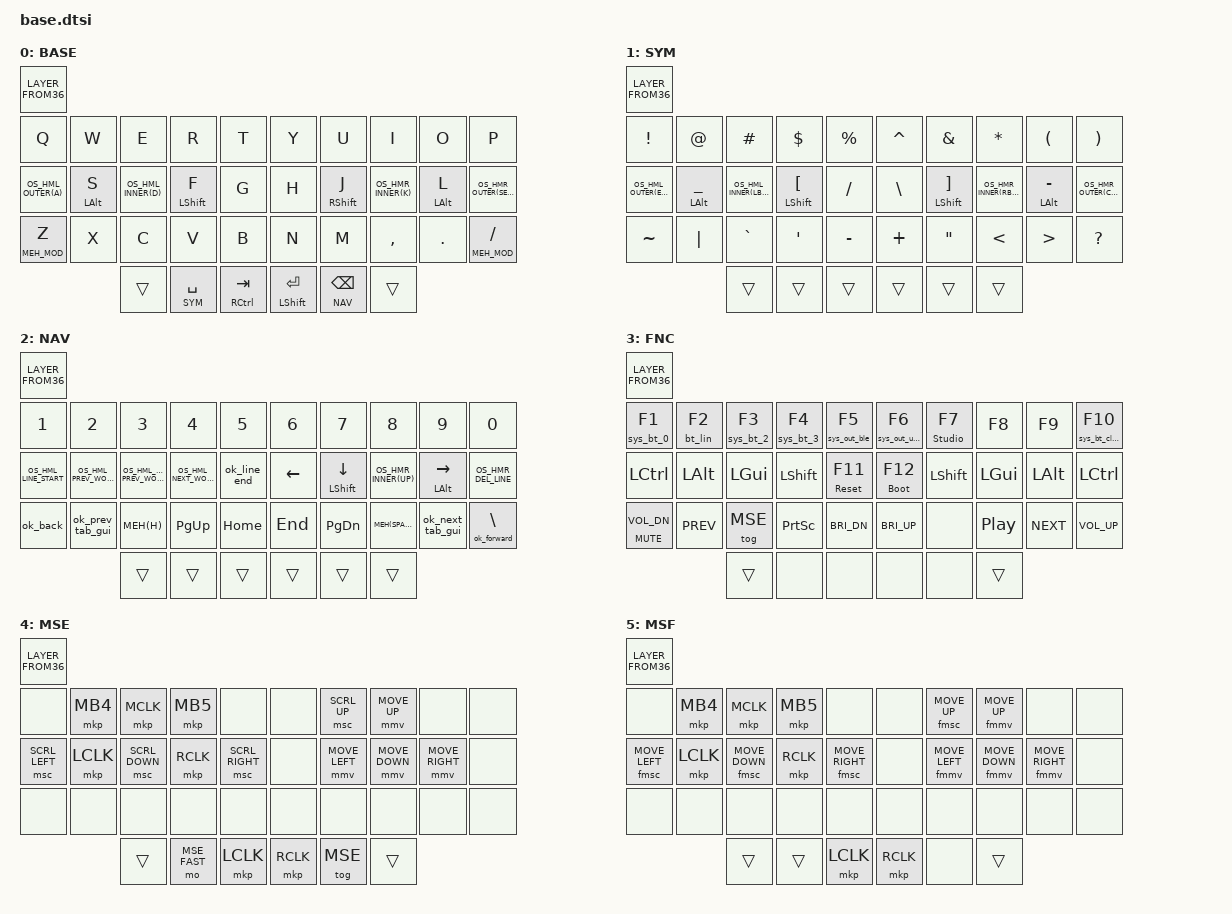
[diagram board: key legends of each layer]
#include <behaviors.dtsi>
#include <dt-bindings/zmk/keys.h>
#include <dt-bindings/zmk/bt.h>
#include <dt-bindings/zmk/oskey.h>
#include <dt-bindings/zmk/outputs.h>
#include <behaviors/rgbled_widget.dtsi> // rgb led indicator for battery and connection
#include <behaviors/case_mode.dtsi> // case_modes behaviors

// Layer definitions
#define BASE 0
#define SYM 1
#define NAV 2
#define FNC 3
#define MSE 4
#define MSE_FAST 5

#define MEH(k) LC(LA(LS(k)))
#define MEH_MOD LA(LS(LCTRL))

#include "mouse.dtsi"
#include "oskey.dtsi"
#include "combos.dtsi"

&caps_word { continue-list = <UNDERSCORE BACKSPACE DELETE MINUS DEL N1 N2 N3 N4 N5 N6 N7 N8 N9 N0>; };

/ {
    macros {
        sys_bt_0: sys_bt_0 {
            compatible = "zmk,behavior-macro";
            #binding-cells = <0>;
            bindings = <&bt BT_SEL 0>;
        };

        bt_lin: bt_lin {
            compatible = "zmk,behavior-macro";
            #binding-cells = <0>;
            bindings = <&bt BT_SEL 1>, <&os_sel OS_LIN>;
        };

        sys_bt_2: sys_bt_2 {
            compatible = "zmk,behavior-macro";
            #binding-cells = <0>;
            bindings = <&bt BT_SEL 2>;
        };

        sys_bt_3: sys_bt_3 {
            compatible = "zmk,behavior-macro";
            #binding-cells = <0>;
            bindings = <&bt BT_SEL 3>;
        };

        sys_out_usb: sys_out_usb {
            compatible = "zmk,behavior-macro";
            #binding-cells = <0>;
            bindings = <&out OUT_USB>;
        };

        sys_out_ble: sys_out_ble {
            compatible = "zmk,behavior-macro";
            #binding-cells = <0>;
            bindings = <&out OUT_BLE>;
        };

        sys_bt_clear: sys_bt_clear {
            compatible = "zmk,behavior-macro";
            #binding-cells = <0>;
            bindings = <&bt BT_CLR>;
        };
    };

   cond_layers {
        compatible = "zmk,conditional-layers";
        // Define FNC layer as tri-state
        func_tristate {
            if-layers = <SYM NAV>;
            then-layer = <FNC>;
        };
    };

    behaviors {
        hmr: hmr {
            compatible = "zmk,behavior-hold-tap";
            bindings = <&kp>, <&kp>;

            #binding-cells = <2>;
            tapping-term-ms = <230>;
            quick-tap-ms = <150>;
            require-prior-idle-ms = <130>;
            flavor = "balanced";
            hold-trigger-key-positions = <KEYS_L THUMBS>;
            hold-trigger-on-release;
        };

        hml: hml {
            compatible = "zmk,behavior-hold-tap";
            bindings = <&kp>, <&kp>;

            #binding-cells = <2>;
            tapping-term-ms = <230>;
            quick-tap-ms = <155>;
            require-prior-idle-ms = <130>;
            flavor = "balanced";
            hold-trigger-key-positions = <KEYS_R THUMBS>;
            hold-trigger-on-release;
        };

        rth: rthumb {
            compatible = "zmk,behavior-hold-tap";
            bindings = <&mo>, <&kp>;
            flavor = "hold-preferred";
            #binding-cells = <2>;
            tapping-term-ms = <200>;
            quick-tap-ms = <130>;
        };

        lth: lthumb {
            compatible = "zmk,behavior-hold-tap";
            bindings = <&mo>, <&kp>;
            flavor = "hold-preferred";
            #binding-cells = <2>;
            tapping-term-ms = <230>;
            quick-tap-ms = <140>;
        };

        hp: hold_priority {
            compatible = "zmk,behavior-hold-tap";
            bindings = <&kp>, <&kp>;
            flavor = "hold-preferred";
            #binding-cells = <2>;
            tapping-term-ms = <230>;
            quick-tap-ms = <150>;
        };

        lsm: left_shift_mode {
            compatible = "zmk,behavior-hold-tap";
            bindings = <&kp>, <&kp>;
            flavor = "hold-preferred";
            #binding-cells = <2>;
            tapping-term-ms = <190>;
            quick-tap-ms = <150>;
            require-prior-idle-ms = <120>;
            hold-trigger-key-positions = <KEYS_R LH0 RH0>;
            //hold-trigger-on-release;
        };

        rsm: right_shift_mode {
            compatible = "zmk,behavior-hold-tap";
            bindings = <&kp>, <&kp>;
            flavor = "hold-preferred";
            #binding-cells = <2>;
            tapping-term-ms = <190>;
            quick-tap-ms = <150>;
            require-prior-idle-ms = <130>;
            hold-trigger-key-positions = <KEYS_L LH0 RH0>;
            //hold-trigger-on-release;
        };

        f1_sys: f1_sys {
            compatible = "zmk,behavior-hold-tap";
            #binding-cells = <2>;
            tapping-term-ms = <3000>;
            flavor = "tap-preferred";
            bindings = <&sys_bt_0>, <&kp>;
        };

        f2_sys: f2_sys {
            compatible = "zmk,behavior-hold-tap";
            #binding-cells = <2>;
            tapping-term-ms = <3000>;
            flavor = "tap-preferred";
            bindings = <&bt_lin>, <&kp>;
        };

        f3_sys: f3_sys {
            compatible = "zmk,behavior-hold-tap";
            #binding-cells = <2>;
            tapping-term-ms = <3000>;
            flavor = "tap-preferred";
            bindings = <&sys_bt_2>, <&kp>;
        };

        f4_sys: f4_sys {
            compatible = "zmk,behavior-hold-tap";
            #binding-cells = <2>;
            tapping-term-ms = <3000>;
            flavor = "tap-preferred";
            bindings = <&sys_bt_3>, <&kp>;
        };

        f5_sys: f5_sys {
            compatible = "zmk,behavior-hold-tap";
            #binding-cells = <2>;
            tapping-term-ms = <3000>;
            flavor = "tap-preferred";
            bindings = <&sys_out_ble>, <&kp>;
        };

        f6_sys: f6_sys {
            compatible = "zmk,behavior-hold-tap";
            #binding-cells = <2>;
            tapping-term-ms = <3000>;
            flavor = "tap-preferred";
            bindings = <&sys_out_usb>, <&kp>;
        };

        f7_sys: f7_sys {
            compatible = "zmk,behavior-hold-tap";
            #binding-cells = <2>;
            tapping-term-ms = <3000>;
            flavor = "tap-preferred";
            bindings = <&studio_unlock>, <&kp>;
        };

        f10_sys: f10_sys {
            compatible = "zmk,behavior-hold-tap";
            #binding-cells = <2>;
            tapping-term-ms = <3000>;
            flavor = "tap-preferred";
            bindings = <&sys_bt_clear>, <&kp>;
        };

        f11_sys: f11_sys {
            compatible = "zmk,behavior-hold-tap";
            #binding-cells = <2>;
            tapping-term-ms = <3000>;
            flavor = "tap-preferred";
            bindings = <&sys_reset>, <&kp>;
        };

        f12_sys: f12_sys {
            compatible = "zmk,behavior-hold-tap";
            #binding-cells = <2>;
            tapping-term-ms = <3000>;
            flavor = "tap-preferred";
            bindings = <&bootloader>, <&kp>;
        };

    };

    keymap {
        compatible = "zmk,keymap";

        base {
            display-name = "BASE";
            bindings = <LAYER_FROM36( \
// ╭─────────────┬─────────────┬─────────────┬─────────────┬─────────────╮   ╭───────────────┬───────────────┬───────────────┬─────────────┬───────────────╮
     &kp Q,        &kp W,        &kp E,        &kp R,        &kp T,            &kp Y,           &kp U,          &kp I,        &kp O,           &kp P,      \
// ├─────────────┼─────────────┼─────────────┼─────────────┼─────────────┤   ├───────────────┼───────────────┼───────────────┼─────────────┼───────────────┤
     OS_HML_OUTER(A), &hml LALT S,  OS_HML_INNER(D), &hml LSHFT F, &kp G,            &kp H,           &hmr RSHFT J, OS_HMR_INNER(K), &hmr LALT L,  OS_HMR_OUTER(SEMI),\
// ├─────────────┼─────────────┼─────────────┼─────────────┼─────────────┤   ├───────────────┼───────────────┼───────────────┼─────────────┼───────────────┤
     &hml MEH_MOD Z,             &kp X,        &kp C,        &kp V,        &kp B,            &kp N,           &kp M,          &kp COMMA,      &kp DOT,     &hmr MEH_MOD SLASH, \
// ╰─────────────┴─────────────┴─────────────┼─────────────┼─────────────┤   ├───────────────┼───────────────┼───────────────┴─────────────┴───────────────╯
                                 &trans,      &lth SYM SPACE, &hp RCTRL TAB,  &hp LSHFT ENTER,  &rth NAV BSPC,   &trans
//                             ╰─────────────┴─────────────┴─────────────╯   ╰───────────────┴───────────────┴─────────────╯
            )>;
        };

        symbol {
          display-name = "SYM";
          bindings = <LAYER_FROM36( \
// ╭───────────────┬───────────────┬───────────────┬────────────────────┬───────────────╮   ╭───────────────┬────────────────────┬────────────────────┬────────────────────┬────────────────────╮
    &kp EXCL,        &kp AT_SIGN,     &kp HASH,        &kp DLLR,           &kp PRCNT,         &kp CARET,       &kp AMPS,            &kp ASTERISK,          &kp LPAR,             &kp RPAR,      \
// ├───────────────┼───────────────┼───────────────┼────────────────────┼───────────────┤   ├───────────────┼────────────────────┼────────────────────┼────────────────────┼────────────────────┤
    OS_HML_OUTER(EQUAL), &hml LALT UNDER, OS_HML_INNER(LBRC), &hml LSHFT LBKT,   &kp SLASH,          &kp BSLH,        &hmr LSHFT RBKT,    OS_HMR_INNER(RBRC),    &hmr LALT MINUS,     OS_HMR_OUTER(COLON), \
// ├───────────────┼───────────────┼───────────────┼────────────────────┼───────────────┤   ├───────────────┼────────────────────┼────────────────────┼────────────────────┼────────────────────┤
      &kp TILDE,       &kp PIPE,       &kp GRAVE,       &kp SQT,            &kp MINUS,         &kp PLUS,        &kp DOUBLE_QUOTES,  &kp LESS_THAN,       &kp GREATER_THAN,     &kp QUESTION,    \
// ╰───────────────┴───────────────┴───────────────┼────────────────────┼───────────────┤   ├───────────────┼────────────────────┴────────────────────┴────────────────────┴────────────────────╯
                                       &trans,          &trans,             &trans,              &trans,        &trans,             &trans       \
//                                 ╰───────────────┴────────────────────┴───────────────╯   ╰───────────────┴────────────────────┴───────────────╯
         )>;
      };

        nav_number {
            display-name = "NAV";
            bindings = <LAYER_FROM36( \
// ╭──────────────────┬───────────────┬────────────────────┬─────────────────┬──────────────╮   ╭────────────────────┬─────────────────┬───────────────┬──────────────────┬─────────────────────╮
     &kp N1,               &kp N2,      &kp N3,              &kp N4,           &kp N5,             &kp N6,             &kp N7,            &kp N8,        &kp N9,            &kp N0,             \
// ├──────────────────┼───────────────┼────────────────────┼─────────────────┼──────────────┤   ├────────────────────┼─────────────────┼───────────────┼──────────────────┼─────────────────────┤
    OS_HML_LINE_START, OS_HML_PREV_WORD, OS_HML_DEL_PREV_WORD, OS_HML_NEXT_WORD, &ok_line_end,     &kp LEFT,          &hmr LSHFT DOWN,  OS_HMR_INNER(UP), &hmr LALT RIGHT,  OS_HMR_DEL_LINE, \
// ├──────────────────┼───────────────┼────────────────────┼─────────────────┼──────────────┤   ├────────────────────┼─────────────────┼───────────────┼──────────────────┼─────────────────────┤
     &ok_back,            &ok_prev_tab_gui, &kp MEH(H),         &kp PG_UP,        &kp HOME,           &kp END,           &kp PG_DN,         &kp MEH(SPACE), &ok_next_tab_gui, &ok_forward,       \
// ╰──────────────────┴───────────────┴────────────────────┼─────────────────┼──────────────┤   ├────────────────────┴─────────────────┴───────────────┴──────────────────┴─────────────────────╯
                                              &trans,        &trans,           &trans,             &trans,               &trans,              &trans   \
//                                    ╰────────────────────┴─────────────────┴──────────────╯   ╰────────────────────┴─────────────────┴───────────────╯
        )>;
      };

        settings_function {
            display-name = "FNC";
            bindings = <LAYER_FROM36( \
// ╭────────────────────┬────────────────────┬────────────────────┬────────────────────┬────────────────────╮   ╭─────────────────┬─────────────────┬───────────────┬───────────────┬────────────────────╮
     &f1_sys 0 F1,         &f2_sys 0 F2,         &f3_sys 0 F3,         &f4_sys 0 F4,       &f5_sys 0 F5,           &f6_sys 0 F6,     &f7_sys 0 F7,   &kp F8,          &kp F9,          &f10_sys 0 F10, \
// ├────────────────────┼────────────────────┼────────────────────┼────────────────────┼────────────────────┤   ├─────────────────┼─────────────────┼───────────────┼───────────────┼────────────────────┤
     &kp LCTRL,            &kp LALT,             &kp LGUI,             &kp LSHFT,         &f11_sys 0 F11,           &f12_sys 0 F12,   &kp LSHFT,       &kp LGUI,        &kp LALT,        &kp LCTRL,       \
// ├────────────────────┼────────────────────┼────────────────────┼────────────────────┼────────────────────┤   ├─────────────────┼─────────────────┼───────────────┼───────────────┼────────────────────┤
     &hp C_MUTE C_VOL_DN, &kp C_PREV,            &tog MSE,            &kp PSCRN,         &kp C_BRI_DN,            &kp C_BRI_UP,      &none,           &kp C_PP,        &kp C_NEXT,      &kp C_VOL_UP,    \
// ╰────────────────────┴────────────────────┴────────────────────┼────────────────────┼────────────────────┤   ├─────────────────┴─────────────────┴───────────────┴───────────────┴────────────────────╯
                                                &trans,               &none,               &none,                  &none,            &none,           &trans         \
//                                           ╰────────────────────┴────────────────────┴────────────────────╯   ╰─────────────────┴─────────────────┴────────────────╯
         )>;
      };

        mouse_layer {
            display-name = "MSE";
            bindings = <LAYER_FROM36( \
// ╭────────────────────┬───────────────┬────────────────────┬───────────────┬────────────────────╮   ╭─────────────────┬────────────────────┬────────────────────┬────────────────────┬────────────────────╮
     &none,               &mkp MB4,         &mkp MCLK,          &mkp MB5,      &none,                   &none,                &msc SCRL_UP,       &mmv MOVE_UP,       &none,                 &none,         \
// ├────────────────────┼───────────────┼────────────────────┼───────────────┼────────────────────┤   ├─────────────────┼────────────────────┼────────────────────┼────────────────────┼────────────────────┤
     &msc SCRL_LEFT,      &mkp LCLK,        &msc SCRL_DOWN,     &mkp RCLK,     &msc SCRL_RIGHT,         &none,                &mmv MOVE_LEFT,     &mmv MOVE_DOWN,    &mmv MOVE_RIGHT,        &none,         \
// ├────────────────────┼───────────────┼────────────────────┼───────────────┼────────────────────┤   ├─────────────────┼────────────────────┼────────────────────┼────────────────────┼────────────────────┤
     &none,               &none,            &none,              &none,         &none,                    &none,                &none,                 &none,         &none,                  &none,         \
// ╰────────────────────┴───────────────┴────────────────────┼───────────────┼────────────────────┤   ├─────────────────┴────────────────────┴────────────────────┴────────────────────┴────────────────────╯
                                                &trans,         &mo MSE_FAST,  &mkp LCLK,               &mkp RCLK,            &tog MSE,              &trans       \
//                                      ╰────────────────────┴───────────────┴────────────────────╯   ╰─────────────────┴────────────────────┴────────────────────╯
         )>;
        };

        mouse_layer_fast {
            display-name = "MSF";
            bindings = <LAYER_FROM36( \
// ╭────────────────────┬───────────────┬────────────────────┬───────────────┬────────────────────╮   ╭─────────────────┬────────────────────┬────────────────────┬────────────────────┬────────────────────╮
     &none,               &mkp MB4,         &mkp MCLK,          &mkp MB5,      &none,                   &none,                &fmsc MOVE_UP,      &fmmv MOVE_UP,      &none,                 &none,         \
// ├────────────────────┼───────────────┼────────────────────┼───────────────┼────────────────────┤   ├─────────────────┼────────────────────┼────────────────────┼────────────────────┼────────────────────┤
     &fmsc MOVE_LEFT,     &mkp LCLK,        &fmsc MOVE_DOWN,    &mkp RCLK,     &fmsc MOVE_RIGHT,        &none,                &fmmv MOVE_LEFT,    &fmmv MOVE_DOWN,   &fmmv MOVE_RIGHT,       &none,         \
// ├────────────────────┼───────────────┼────────────────────┼───────────────┼────────────────────┤   ├─────────────────┼────────────────────┼────────────────────┼────────────────────┼────────────────────┤
     &none,               &none,            &none,              &none,         &none,                    &none,                &none,                 &none,         &none,                  &none,         \
// ╰────────────────────┴───────────────┴────────────────────┼───────────────┼────────────────────┤   ├─────────────────┴────────────────────┴────────────────────┴────────────────────┴────────────────────╯
                                                &trans,         &trans,        &mkp LCLK,               &mkp RCLK,            &none,              &trans       \
//                                      ╰────────────────────┴───────────────┴────────────────────╯   ╰─────────────────┴────────────────────┴────────────────────╯
         )>;
        };
    };

};
